# F28x7x_cla_regs register map
Vendor: Texas Instruments
Peripheral module from a debugger description file (folder C2000).
Address unit: 16 bits
Registers are 16-bit, read-write, no defined reset value unless marked. A register's access mark holds for its fields unless they carry their own. Offsets are as the file gives them; lines under a group give offsets from that group; [hi:lo] are bit positions; {n}, {i} and the like mark numbered series; 'fields as' and 'values as' point back to an identical list; <NAME> marks a mode.

## CLA_REGS
0x00 MVECT1 — Task Interrupt Vector
  [15:0] MVECT — Offset of the first instruction
0x01 MVECT2 — Task Interrupt Vector
  [15:0] MVECT — Offset of the first instruction
0x02 MVECT3 — Task Interrupt Vector
  [15:0] MVECT — Offset of the first instruction
0x03 MVECT4 — Task Interrupt Vector
  [15:0] MVECT — Offset of the first instruction
0x04 MVECT5 — Task Interrupt Vector
  [15:0] MVECT — Offset of the first instruction
0x05 MVECT6 — Task Interrupt Vector
  [15:0] MVECT — Offset of the first instruction
0x06 MVECT7 — Task Interrupt Vector
  [15:0] MVECT — Offset of the first instruction
0x07 MVECT8 — Task Interrupt Vector
  [15:0] MVECT — Offset of the first instruction
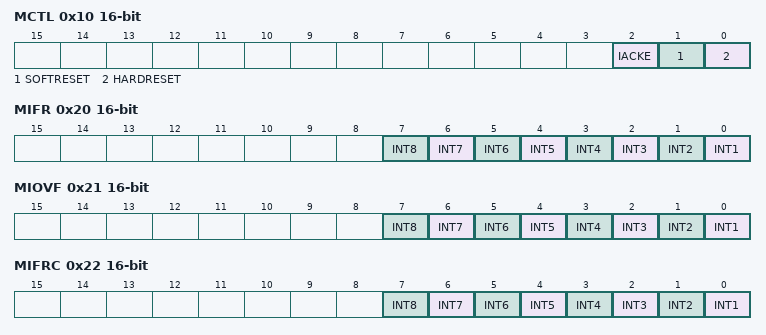
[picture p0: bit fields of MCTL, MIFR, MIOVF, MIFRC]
0x10 MCTL — Control Register
  [2] IACKE — IACK enable
    0=The CLA ignores the IACK instruction. (default); 1=Enable the main CPU to use the IACK #16bit instruction to set M
  [1] SOFTRESET
    0=This bit always reads back 0 and writes of 0 are ignored; 1=Writing a 1 will cause a soft reset of the CLA
  [0] HARDRESET
    0=This bit always reads back 0 and writes of 0 are ignored; 1=Writing a 1 will cause a hard reset of the CLA
0x20 MIFR — Interrupt Flag Register
  [n-1] INT{n} (n=1..8) — Task {n} Interrupt Flag
    0=TASK_FLAG_DISABLE[[br]]Task {n} interrupt is currently not flagge; 1=TASK_FLAG_ENABLE[[br]]Task {n} interrupt has been received and is
0x21 MIOVF — Interrupt Overflow Flag Register
  [n-1] INT{n} (n=1..8) — Task {n} Interrupt Overflow Flag
    0=A task {n} interrupt overflow has not occurred (default); 1=A task {n} interrupt overflow has occurred
0x22 MIFRC — Interrupt Force Register
  [n-1] INT{n} (n=1..8) — Task {n} Interrupt Force
    0=This bit always reads back 0 and writes of 0 have no effect; 1=Write a 1 to force the task {n} interrupt
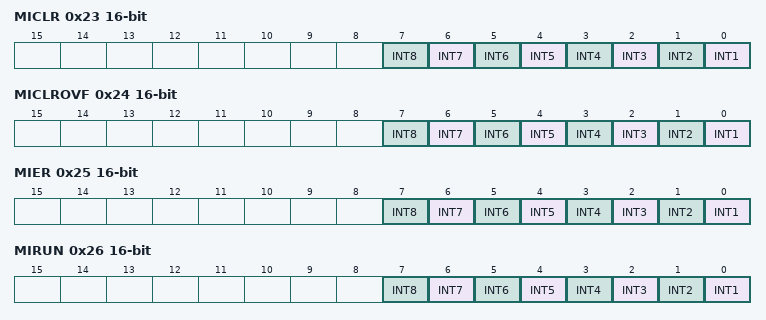
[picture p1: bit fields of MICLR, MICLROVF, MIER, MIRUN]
0x23 MICLR — Interrupt Flag Clear Register
  [n-1] INT{n} (n=1..8) — Task {n} Interrupt Flag Clear
    0=This bit always reads back 0 and writes of 0 have no effect; 1=Write a 1 to clear the task {n} interrupt flag
0x24 MICLROVF — Interrupt Overflow Flag Clear Register
  [n-1] INT{n} (n=1..8) — Task {n} Interrupt Overflow Flag Clear
    0=This bit always reads back 0 and writes of 0 have no effect; 1=Write a 1 to clear the task {n} interrupt overflow flag
0x25 MIER — Interrupt Enable Register
  [n-1] INT{n} (n=1..8) — Task {n} Interrupt Enable
    0=TASK_INT_DISABLE[[br]]Task {n} interrupt is disabled (default); 1=TASK_INT_ENABLE[[br]]Task {n} interrupt is enabled
0x26 MIRUN — Interrupt Run Status Register
  [n-1] INT{n} (n=1..8) — Task {n} Run Status
    0=Task {n} is not executing (default); 1=Task {n} is executing
0x28 _MPC — CLA Program Counter
  [15:0] _MPC — Points to the instruction
0x2A _MAR0 — CLA Auxiliary Register 0
  [15:0] _MAR0 — CLA Auxillary Register 0
0x2B _MAR1 — CLA Auxiliary Register 1
  [15:0] _MAR1 — CLA Auxillary Register 1
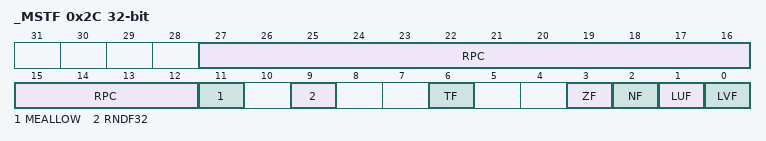
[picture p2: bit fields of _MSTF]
0x2C _MSTF 32-bit — CLA Floating-Point Status Register
  [27:12] RPC — Return PC
  [11] MEALLOW — MEALLOW Status
    0=The CLA cannot write to EALLOW protected registers; 1=The CLA is allowed to write to EALLOW protected registers
  [9] RNDF32 — Round 32-bit Floating-Point Mode
    0=If this bit is zero, the MMPYF32, MADDF32 and MSUBF32 instructi; 1=If this bit is one, the MMPYF32, MADDF32 and MSUBF32 instructio
  [6] TF — Test Flag
    0=The condition tested with the MTESTTF instruction is false; 1=The condition tested with the MTESTTF instruction is true
  [3] ZF — Zero Float Flag
    0=The value is not zero; 1=The value is zero
  [2] NF — Negative Float Flag
    0=The value is not negative; 1=The value is negative
  [1] LUF — Latched Underflow Flag
    0=An underflow condition has not been latched; 1=An underflow condition has been latched
  [0] LVF — Latched Overflow Flag
    0=An overflow condition has not been latched; 1=An overflow condition has been latched
{0x2E+4i} _MR{i} 32-bit (i=0..3) — CLA Floating-Point Result Register {i}
  [31:0] i32 — CLA Result Register {i}
